# AU302PDF51 register map
File version: 1.0
Registers are 32-bit, access per field, reset 0x0 unless marked. A register's access mark holds for its fields unless they carry their own. Offsets are from the block's base; [hi:lo] are bit positions; {n}, {i} and the like mark numbered series.

## DAC0 — 数模转换器
Base 0x18300000
Same registers: DAC1 0x18301000, DAC2 0x18302000
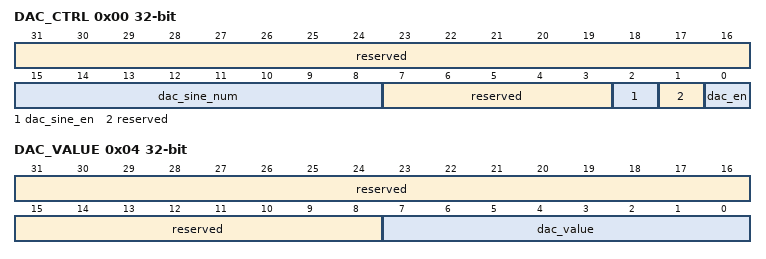
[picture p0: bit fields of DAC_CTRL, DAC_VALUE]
0x00 DAC_CTRL — DAC控制寄存器
  [31:16] reserved ro — 保留。
  [15:8] dac_sine_num rw — DAC 正弦波间隔计数值（时钟 10M 时，输出 0.3Msps 正弦波，配置为 0x21）。
  [7:3] reserved ro — 保留。
  [2] dac_sine_en rw — DAC 正弦波模式使能。0：不使能；1：使能。
  [1] reserved ro — 保留。
  [0] dac_en rw — DAC 使能。0：不使能；1：使能。
0x04 DAC_VALUE — 配置值寄存器
  [31:8] reserved ro — 保留。
  [7:0] dac_value rw — DAC 数字信号，对应电压 V=(dac_value*(VDDA−VSSA)) / 256。

## GPIO0 — GPIO
Base 0x14500000
Same registers: GPIO1 0x14501000, GPIO2 0x14502000, GPIO3 0x14503000, GPIO4 0x14504000, GPIO5 0x14505000, GPIO6 0x14506000, GPIO7 0x14507000
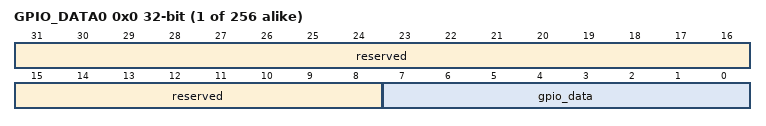
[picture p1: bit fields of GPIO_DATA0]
{0x0+4i} GPIO_DATA{i} (i=0..255) — GPIO_DATA 为 GPIO 数据寄存器，用来对输入或输出数据进行缓存。
  [31:8] reserved ro — 保留。
  [7:0] gpio_data rw — 当 GPIO 配置为输入模式时，为 GPIO 输入数据；当 GPIO 配置为输出模式时，为输出数据。各比特均可独立控制。与GPIO_DIR 配合使用。
0x400 GPIO_DIR 8-bit rw — GPIO_DIR 为 GPIO 方向控制寄存器。用来配置 GPIO 方向。
  [7:0] gpio_dir — GPIO 方向控制寄存器。 bit[7:0]分别对应GPIO_DATA bit[7:0]，各比特可独立控制。 0：输入；1：输出。
0x404 GPIO_IS 8-bit rw — GPIO_IS 为 GPIO 中断触发寄存器。用来配置 GPIO 触发电平方式。
  [7:0] gpio_is — GPIO 中断触发控制寄存器， bit[7:0]分别对 应 GPIO_DATA bit[7:0]，各比特独立控 制。 0：边沿触发中断； 1：电平触发中断。
0x408 GPIO_IBE 8-bit rw — GGPIO_IBE 为 GPIO 双沿触发中断寄存器。用来配置 GPIO 沿触发方式
  [7:0] gpio_ibe — GPIO 中断沿触发控制寄存器， bit[7:0]分别 对应 GPIO_DATA bit[7:0]，各比特独立控 制。 0：单边沿触发中断，具体是上升沿还是下 降沿触发由 GPIO_IEV 控制； 1：双边触发中断。
0x40C GPIO_IEV 8-bit rw — GPIO_IEV 为 GPIO 触发中断条件寄存器。用来配置 GPIO 触发中断条件。
  [7:0] gpio_iev — GPIO 触发中断条件寄存器， bit[7:0]分别对 应 GPIO_DATA bit[7:0]，各比特独立控 制。 0：下降沿或低电平触发中断，具体由 GPIO_IS 控制； 1：上升沿或高电平触发中断。
0x410 GPIO_IE 8-bit rw — GPIO_IE 为 GPIO 中断屏蔽寄存器。用来屏蔽 GPIO 中断。
  [7:0] gpio_ie — GPIO 中断屏蔽寄存器， bit[7:0]分别对应 GPIO_DATA bit[7:0]，各比特独立控制。 0：屏蔽中断；1：不屏蔽中断。
0x414 GPIO_RIS 8-bit rw — GPIO_RIS 为 GPIO 原始中断状态寄存器。用来查询 GPIO 原始中断状态。
  [7:0] gpio_ris — GPIO 原始中断寄存器， bit[7:0]分别对应 GPIO_DATA bit[7:0]，指示未屏蔽的中断 状态。该状态不受 GPIO_IE 寄存器屏蔽控 制。 0：未发生中断； 1：已发生中断。
0x418 GPIO_MIS 8-bit rw — GPIO_MIS 为 GPIO 屏蔽状态中断寄存器。用来查询 GPIO 屏蔽后的中断状态。对所 有位进行或操作得到中断输出 gpio_int。
  [7:0] gpio_mis — GPIO 屏蔽后中断寄存器， bit[7:0]分别对应 GPIO_DATA bit[7:0]，指示经屏蔽后的中 断状态。该状态受 GPIO_IE 寄存器屏蔽控 制。 0：中断无效； 1：中断有效。
0x41C GPIO_IC 8-bit wo — GPIO_IC 为 GPIO 中断清除寄存器。用来清除 GPIO 产生的中断，同时清除 GPIO_RIS 寄存器和 GPIO_MIS 寄存器。
  [7:0] gpio_ic — GPIO 中断清除寄存器， bit[7:0]分别对应 GPIO_DATA bit[7:0]，各比特可独立控 制。 0：无影响； 1：清除中断。

## GPT0
Base 0x14700000
Same registers: GPT1 0x14701000
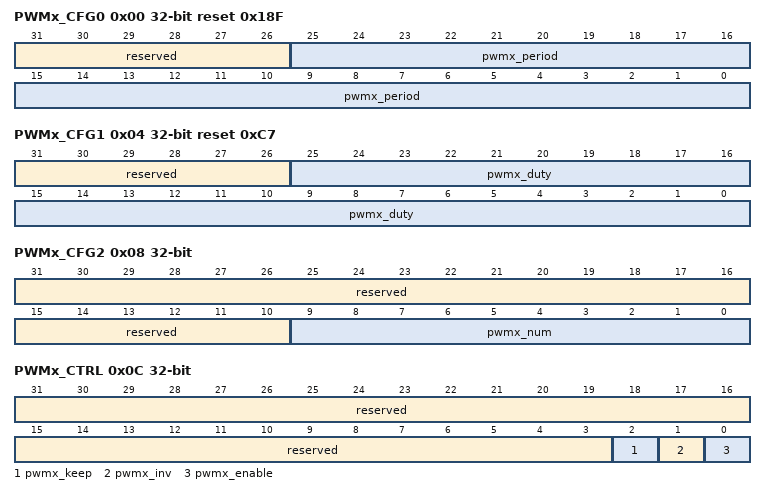
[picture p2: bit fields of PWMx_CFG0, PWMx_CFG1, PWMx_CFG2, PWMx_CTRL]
0x00 PWMx_CFG0 reset 0x18F — PWMx_CFG0 为 GPTx 的配置寄存器 0。
  [31:26] reserved ro — 保留。
  [25:0] pwmx_period rw — GPTx 的周期数。 注意： 要求配置值必须 ≥ 2。
0x04 PWMx_CFG1 reset 0xC7 — PWMx_CFG1 为 GPTx 的配置寄存器 1。
  [31:26] reserved ro — 保留。
  [25:0] pwmx_duty read-right — GPTx 的高电平拍数，如果大于等于周期 数，则输出一直为高电平。 注意： 要求配置值必须 ≥ 1。
0x08 PWMx_CFG2 — PWMx_CFG2 为 GPTx 的配置寄存器 2。
  [31:10] reserved ro — 保留。
  [9:0] pwmx_num rw — GPTx 输出方波的数目。
0x0C PWMx_CTRL — PWMx_CTRL 为 GPTx 的控制寄存器。
  [31:3] reserved ro — 保留。
  [2] pwmx_keep rw — GPTx 输出模式。 0： GPTx 输出固定数目的方波； 1： GPTx 一直输出方波。
  [1] pwmx_inv rw — GPTx 输出正反相控制。 0： GPTx 正常输出方波； 1： GPTx 反相输出方波。
  [0] pwmx_enable rw — GPTx 使能控制。0： GPTx 模块关闭；1： GPTx 模块使能。
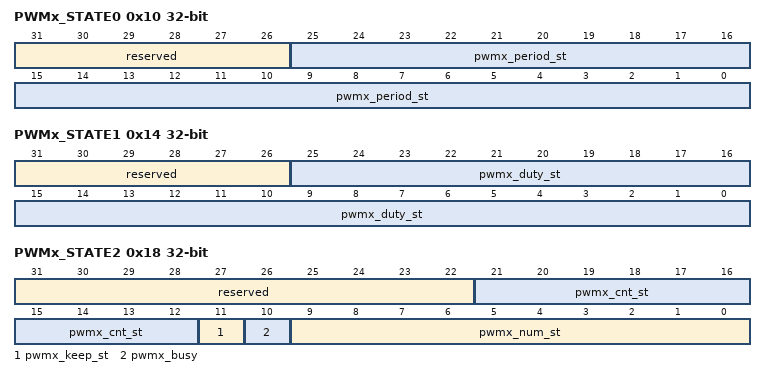
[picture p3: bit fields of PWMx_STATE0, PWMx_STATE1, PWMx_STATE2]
0x10 PWMx_STATE0 — PWMx_STATE0 为 GPTx 的状态寄存器 0。
  [31:26] reserved ro — 保留。
  [25:0] pwmx_period_st rw — GPTx 的内部模块采用的计数周期数。
0x14 PWMx_STATE1 — PWMx_STATE1 为 GPTx 的状态寄存器 1。
  [31:26] reserved ro — 保留。
  [25:0] pwmx_duty_st rw — GPTx 的内部模块采用的高电平拍数。
0x18 PWMx_STATE2 ro — PWMx_STATE2 为 GPTx 的状态寄存器 2。
  [31:22] reserved — 保留。
  [21:12] pwmx_cnt_st — GPTx 模块剩余输出的方波数目。只有当 pwmx_busy==1， pwmx_keep_st==0 时才 有意义。
  [11] pwmx_keep_st — GPTx 的内部模块采用的输出方波的模 式。 0：输出固定数目的方波； 1：一直输出方波。
  [10] pwmx_busy — GPTx 模块的工作状态。 0：空闲，输出完成； 1：正在输出方波。
  [9:0] pwmx_num_st — GPTx 的内部模块采用的输出方波数目。

## IOCMG_AON — IOCMG_AON peripheral interface
Base 0x147E0000
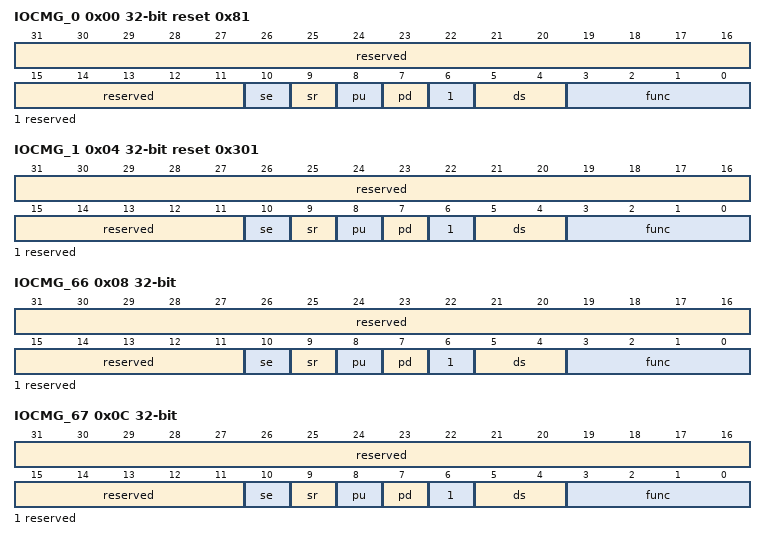
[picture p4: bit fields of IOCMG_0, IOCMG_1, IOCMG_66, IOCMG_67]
0x00 IOCMG_0 reset 0x81 — TCK/SWDCK 管脚配置寄存器。
  [31:11] reserved ro — 保留。
  [10] se rw — 管脚施密特输入控制。 0：关闭； 1：打开。
  [9] sr rw — 管脚电平转换速率控制。 0：快沿输出； 1：慢沿输出。
  [8] pu rw — 管脚上拉控制。 0：关闭； 1：打开。
  [7] pd rw — 管脚下拉控制。 0：关闭； 1：打开。
  [6] reserved ro — 保留。
  [5:4] ds rw — 管脚驱动能力选择（档位越大，驱动能力越大）。 00：档位4； 01：档位3； 10：档位2； 11：档位1；
  [3:0] func rw — 功能选择。 0x0: GPIO0_0； 0x1: JTAG_TCK； 0x3: DS_WAKEUP0； 其它: 保留。
0x04 IOCMG_1 reset 0x301 — TMS/SWDIO 管脚配置寄存器。
  [31:11] reserved ro — 保留。
  [10] se rw — 管脚施密特输入控制。 0：关闭； 1：打开。
  [9] sr rw — 管脚电平转换速率控制。 0：快沿输出； 1：慢沿输出。
  [8] pu rw — 管脚上拉控制。 0：关闭； 1：打开。
  [7] pd rw — 管脚下拉控制。 0：关闭； 1：打开。
  [6] reserved ro — 保留。
  [5:4] ds rw — 管脚驱动能力选择（档位越大，驱动能力越大）。 00：档位4； 01：档位3； 10：档位2； 11：档位1。
  [3:0] func rw — 功能选择。 0x0: GPIO0_1； 0x1: JTAG_TMS； 0x3: DS_WAKEUP1； 其它: 保留。
0x08 IOCMG_66 — I2C0_SCL/UART2_TX 管脚配置寄存器。
  [31:11] reserved ro — 保留。
  [10] se rw — 管脚施密特输入控制。 0：关闭； 1：打开。
  [9] sr rw — 管脚电平转换速率控制。 0：快沿输出； 1：慢沿输出。
  [8] pu rw — 管脚上拉控制。 0：关闭； 1：打开。
  [7] pd rw — 管脚下拉控制。 0：关闭； 1：打开。
  [6] reserved ro — 保留。
  [5:4] ds rw — 管脚驱动能力选择（档位越大，驱动能力越大）。 00：档位4； 01：档位3； 10：档位2； 11：档位1。
  [3:0] func rw — 功能选择。 0x0: GPIO7_6； 0x1: UART2_TXD； 0x2: I2C0_SCL； 0x3: DS_WAKEUP2； 0x4: APT_EVTIO4； 0x8: ADC2_ANA_A3； 其它: 保留。
0x0C IOCMG_67 — I2C0_SDA/UART2_RX 管脚配置寄存器。
  [31:11] reserved ro — 保留。
  [10] se rw — 管脚施密特输入控制。 0：关闭； 1：打开。
  [9] sr rw — 管脚电平转换速率控制。 0：快沿输出； 1：慢沿输出。
  [8] pu rw — 管脚上拉控制。 0：关闭； 1：打开。
  [7] pd rw — 管脚下拉控制。 0：关闭； 1：打开。
  [6] reserved ro — 保留。
  [5:4] ds rw — 管脚驱动能力选择（档位越大，驱动能力越大）。 00：档位4； 01：档位3； 10：档位2； 11：档位1。
  [3:0] func rw — 功能选择。 0x0: GPIO7_7； 0x1: UART2_RXD； 0x2: I2C0_SDA； 0x3: DS_WAKEUP3； 0x8: ADC2_ANA_A4； 其它: 保留。
